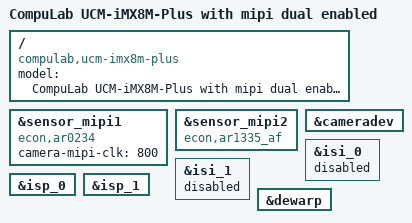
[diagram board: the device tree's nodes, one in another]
// SPDX-License-Identifier: (GPL-2.0+ OR MIT)
/*
 * Copyright 2021 CompuLab
 */

/dts-v1/;

#include "ucm-imx8m-plus.dts"
#include "ucm-imx8m-plus_mipi-csi1.dtsi"
#include "ucm-imx8m-plus_mipi-csi2.dtsi"

/ {
	model = "CompuLab UCM-iMX8M-Plus with mipi dual enabled";
	compatible = "compulab,ucm-imx8m-plus", "fsl,imx8mp";
};

&sensor_mipi1 {
	compatible = "econ,ar0234", "ar0234";
	camera-mipi-clk = <800>;
};

&sensor_mipi2 {
	/delete-property/ pinctrl-0;
	compatible = "econ,ar1335_af", "ar1335_af";
};

&cameradev {
	status = "okay";
};

&isi_0 {
	status = "disabled";
};

&isi_1 {
	status = "disabled";
};

&isp_0 {
	status = "okay";
};

&isp_1 {
	status = "okay";
};

&dewarp {
	status = "okay";
};
